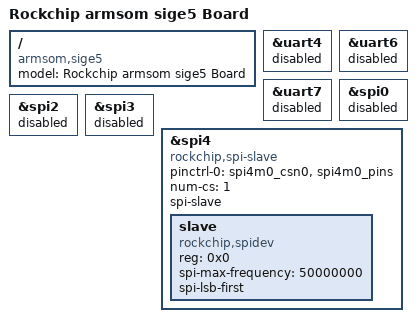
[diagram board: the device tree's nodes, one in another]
// SPDX-License-Identifier: (GPL-2.0+ OR MIT)
/*
 * Copyright (c) 2024 Rockchip Electronics Co., Ltd.
 * rk3576-evb1-v10-linux.dts
 */

/dts-v1/;

#include "rk3576-armsom-sige5.dtsi"
//#include "rk3576-armsom-sige5-camera-ov13850.dtsi"
//#include "rk3576-armsom-sige5-display-10hd.dtsi"
#include "rk3576-linux.dtsi"

/ {
	model = "Rockchip armsom sige5 Board";
	compatible = "armsom,sige5", "rockchip,rk3576";
};

&uart4 {
	status = "disabled";
};

&uart6 {
	status = "disabled";
};

&uart7 {
	status = "disabled";
};

&spi0 {
	status = "disabled";
};

&spi2 {
	status = "disabled";
};

&spi3 {
	status = "disabled";
};

&spi4 {
	compatible = "rockchip,spi-slave";
	pinctrl-0 = <&spi4m0_csn0 &spi4m0_pins>;
	num-cs = <1>;
	spi-slave;
	status = "okay";

	slave {
//		compatible = "rockchip,spi_test_bus4_cs0";
		compatible = "rockchip,spidev";
		reg = <0x0>;
		spi-max-frequency = <50000000>;
		spi-lsb-first;
		status = "okay";
	};
};
